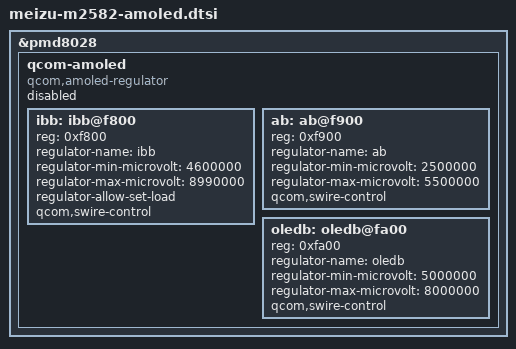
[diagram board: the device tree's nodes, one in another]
// SPDX-License-Identifier: BSD-3-Clause
/*
 * M2582: AMOLED display power (ELVDD / ELVSS / OLEDB) on the PMD802x.
 *
 * Disabled, deliberately, to match the factory device tree. The bootloader
 * brings these rails up through its own XBL service (default-elvdd /
 * default-elvss / default-oledb) and leaves them running, and the factory
 * panel node never references them -- so a working display does not depend
 * on Linux owning this power.
 *
 * The block is kept for the rail map and the voltage ranges taken from the
 * factory tree. It cannot probe as written: every SPMI access to the PMD8028
 * (slave 4) is rejected by the hardware with "transaction failed", so the
 * driver never reads PERIPH_REVISION4.
 */

&pmd8028 {
	qcom-amoled {
		compatible = "qcom,amoled-regulator";
		#address-cells = <1>;
		#size-cells = <0>;

		/* Not probed: see the note above. */
		status = "disabled";

		/*
		 * IBB: the negative rail (ELVSS).
		 * Range taken from the factory tree: 4.6 V .. 8.99 V.
		 */
		ibb: ibb@f800 {
			reg = <0xf800>;
			reg-names = "ibb_base";
			regulator-name = "ibb";
			regulator-min-microvolt = <4600000>;
			regulator-max-microvolt = <8990000>;
			regulator-allow-set-load;
			qcom,swire-control;
		};

		/*
		 * AB: the positive rail (ELVDD).
		 * Factory range: 2.5 V .. 5.5 V.
		 */
		ab: ab@f900 {
			reg = <0xf900>;
			reg-names = "ab_base";
			regulator-name = "ab";
			regulator-min-microvolt = <2500000>;
			regulator-max-microvolt = <5500000>;
			qcom,swire-control;
		};

		/*
		 * OLEDB: the boost converter that feeds the above.
		 * Factory range: 5.0 V .. 8.0 V.
		 */
		oledb: oledb@fa00 {
			reg = <0xfa00>;
			reg-names = "oledb_base";
			regulator-name = "oledb";
			regulator-min-microvolt = <5000000>;
			regulator-max-microvolt = <8000000>;
			qcom,swire-control;
		};
	};
};
